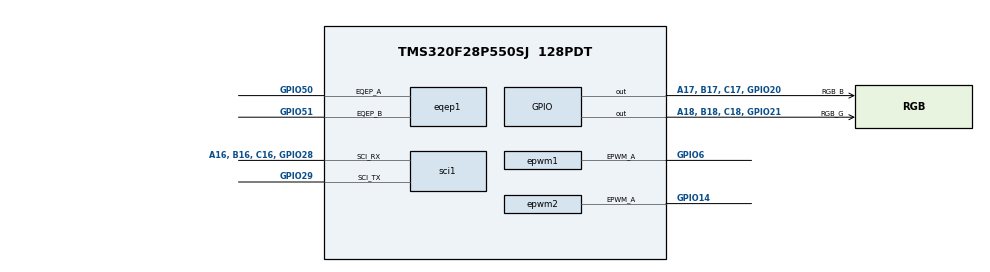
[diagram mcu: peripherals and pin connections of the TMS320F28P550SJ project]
/**
 * These arguments were used when this file was generated. They will be automatically applied on subsequent loads
 * via the GUI or CLI. Run CLI with '--help' for additional information on how to override these arguments.
 * @cliArgs --device "F28P55x" --part "F28P55x_128PDT" --package "128PDT" --context "system" --product "C2000WARE@5.04.00.00"
 * @v2CliArgs --device "TMS320F28P550SJ" --package "128PDT" --variant "TMS320F28P550SJ9" --context "system" --product "C2000WARE@5.04.00.00"
 * @versions {"tool":"1.23.0+4000"}
 */

/**
 * Import the modules used in this configuration.
 */
const epwm  = scripting.addModule("/driverlib/epwm.js", {}, false);
const epwm1 = epwm.addInstance();
const epwm2 = epwm.addInstance();
const eqep  = scripting.addModule("/driverlib/eqep.js", {}, false);
const eqep1 = eqep.addInstance();
const gpio  = scripting.addModule("/driverlib/gpio.js", {}, false);
const gpio1 = gpio.addInstance();
const gpio2 = gpio.addInstance();
const sci   = scripting.addModule("/driverlib/sci.js", {}, false);
const sci1  = sci.addInstance();

/**
 * Write custom configuration values to the imported modules.
 */
epwm1.epwmTimebase_hsClockDiv                                    = "EPWM_HSCLOCK_DIVIDER_1";
epwm1.epwmTimebase_period                                        = 10000;
epwm1.epwmTimebase_counterMode                                   = "EPWM_COUNTER_MODE_UP_DOWN";
epwm1.epwmActionQualifier_EPWM_AQ_OUTPUT_A_ON_TIMEBASE_UP_CMPA   = "EPWM_AQ_OUTPUT_LOW";
epwm1.epwmActionQualifier_EPWM_AQ_OUTPUT_A_ON_TIMEBASE_DOWN_CMPA = "EPWM_AQ_OUTPUT_HIGH";
epwm1.useCase                                                    = "CUSTOM";
epwm1.useInterfacePins                                           = ["EPWM#_A"];
epwm1.$name                                                      = "Module_PWM_M";
epwm1.epwm.$assign                                               = "EPWM4";
epwm1.epwm.epwm_aPin.$assign                                     = "GPIO6";

epwm2.epwmTimebase_hsClockDiv                                    = "EPWM_HSCLOCK_DIVIDER_1";
epwm2.epwmTimebase_period                                        = 10000;
epwm2.epwmTimebase_counterMode                                   = "EPWM_COUNTER_MODE_UP_DOWN";
epwm2.epwmActionQualifier_EPWM_AQ_OUTPUT_A_ON_TIMEBASE_UP_CMPA   = "EPWM_AQ_OUTPUT_LOW";
epwm2.epwmActionQualifier_EPWM_AQ_OUTPUT_A_ON_TIMEBASE_DOWN_CMPA = "EPWM_AQ_OUTPUT_HIGH";
epwm2.useCase                                                    = "CUSTOM";
epwm2.useInterfacePins                                           = ["EPWM#_A"];
epwm2.$name                                                      = "Module_PWM_P";
epwm2.epwm.$assign                                               = "EPWM8";
epwm2.epwm.epwm_aPin.$assign                                     = "GPIO14";

eqep1.eqepResolution          = "EQEP_CONFIG_1X_RESOLUTION";
eqep1.latchPositionCounter    = "EQEP_LATCH_UNIT_TIME_OUT";
eqep1.swPositionInit          = true;
eqep1.enableModule            = true;
eqep1.enableUnitTimer         = true;
eqep1.enableInterrupt         = true;
eqep1.registerInterrupts      = true;
eqep1.interruptSources        = ["EQEP_INT_UNIT_TIME_OUT"];
eqep1.emulationMode           = "EQEP_EMULATIONMODE_RUNFREE";
eqep1.useInterfacePins        = ["EQEP#_A","EQEP#_B"];
eqep1.$name                   = "Module_EQEP";
eqep1.useCase                 = "CUSTOM";
eqep1.positionCounterMax      = 4294967295;
eqep1.unitTimerPeriod         = 7500000;
eqep1.eqepInt.enableInterrupt = true;
eqep1.eqep.$assign            = "EQEP1";
eqep1.eqep.eqep_aPin.$assign  = "GPIO50";
eqep1.eqep.eqep_bPin.$assign  = "GPIO51";

gpio1.$name             = "RGB_B";
gpio1.direction         = "GPIO_DIR_MODE_OUT";
gpio1.writeInitialValue = true;
gpio1.initialValue      = 1;
gpio1.gpioPin.$assign   = "A17, B17, C17, GPIO20";

gpio2.$name             = "RGB_G";
gpio2.direction         = "GPIO_DIR_MODE_OUT";
gpio2.writeInitialValue = true;
gpio2.initialValue      = 1;
gpio2.gpioPin.$assign   = "A18, B18, C18, GPIO21";

sci1.$name                      = "Debug_Serial";
sci1.selectRegisteredInterrupts = ["registerRxInt"];
sci1.enabledInterrupts          = ["SCI_INT_RXRDY_BRKDT"];
sci1.useFifo                    = false;
sci1.sci.$assign                = "SCIA";
sci1.sci.sci_rxPin.$assign      = "A16, B16, C16, GPIO28";
sci1.sci.sci_txPin.$assign      = "GPIO29";
sci1.rxQual.$name               = "myGPIOQUAL0";
sci1.txQual.$name               = "myGPIOQUAL1";
sci1.sciRXInt.enableInterrupt   = true;
